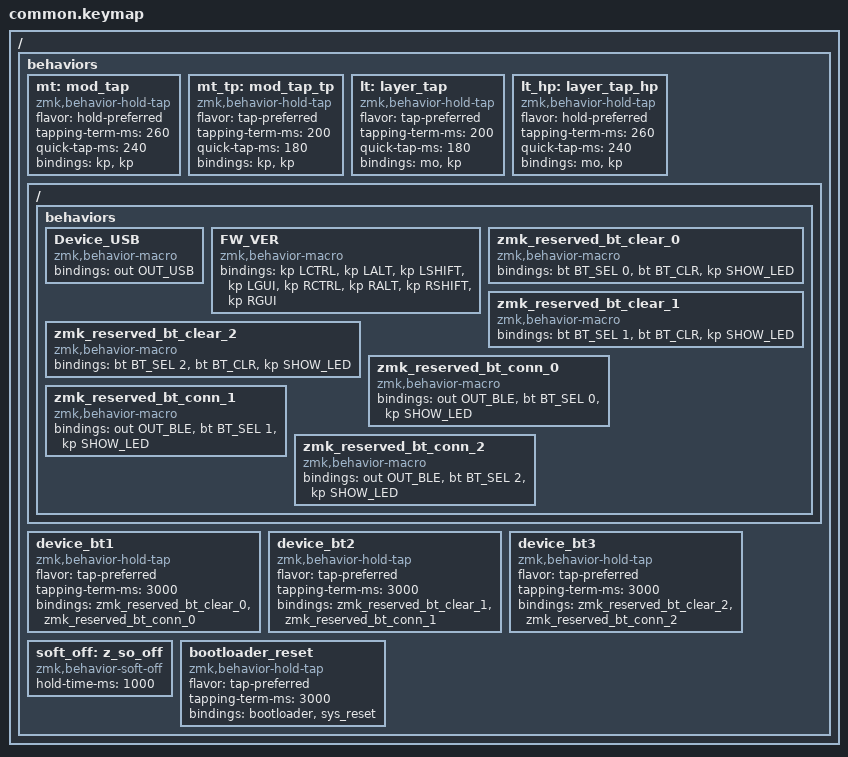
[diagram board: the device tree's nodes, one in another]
/*
 * Copyright (c) 2021 The ZMK Contributors
 *
 * SPDX-License-Identifier: MIT
 */
#define FW_VER zmk_firmware_version_251115
 
#if 0
#define ZMK_BEHAVIORS_OMIT_CAPS_WORD        // &caps_word
#define ZMK_BEHAVIORS_OMIT_KT               // &kt, Key Toggle
#define ZMK_BEHAVIORS_OMIT_KEY_REPEAT       // &key_repeat, Key Repeat
#define ZMK_BEHAVIORS_OMIT_SK               // &sk, Sticky Key
#define ZMK_BEHAVIORS_OMIT_STICKY_LAYER     // &sl, Sticky Layer
#endif

#include <behaviors.dtsi>
#include <dt-bindings/zmk/keys.h>
#include <dt-bindings/zmk/bt.h>
#include <dt-bindings/zmk/outputs.h>

/ {
    behaviors {
        // mt default: hold preferred. Rename it.
        mt: mod_tap {
            compatible = "zmk,behavior-hold-tap";
            #binding-cells = <2>;
            flavor = "hold-preferred";
            tapping-term-ms = <260>;
            quick-tap-ms = <240>;
            bindings = <&kp>, <&kp>;
        };

        // mt_tp tap preferred
        mt_tp: mod_tap_tp {
            compatible = "zmk,behavior-hold-tap";
            #binding-cells = <2>;
            flavor = "tap-preferred";
            tapping-term-ms = <200>;
            quick-tap-ms = <180>;
            bindings = <&kp>, <&kp>;
        };

        // lt default: tap preferred. Rename it.
        lt: layer_tap {
            compatible = "zmk,behavior-hold-tap";
            #binding-cells = <2>;
            flavor = "tap-preferred";
            tapping-term-ms = <200>;
            quick-tap-ms = <180>;
            bindings = <&mo>, <&kp>;
        };

        // lt_hp:  hold preferred
        lt_hp: layer_tap_hp {
            compatible = "zmk,behavior-hold-tap";
            #binding-cells = <2>;
            flavor = "hold-preferred";
            tapping-term-ms = <260>;
            quick-tap-ms = <240>;
            bindings = <&mo>, <&kp>;
        };
        
        #if 1
        ZMK_MACRO(Device_USB, bindings = <&out OUT_USB>;)

        #define SHOW_LED 0xAB //A5-AF Reserved
        ZMK_MACRO(FW_VER, bindings = <&kp LCTRL &kp LALT &kp LSHIFT &kp LGUI &kp RCTRL &kp RALT &kp RSHIFT &kp RGUI>;)
        ZMK_MACRO(zmk_reserved_bt_clear_0, bindings = <&bt BT_SEL 0>, <&bt BT_CLR>, <&kp SHOW_LED>;)
        ZMK_MACRO(zmk_reserved_bt_clear_1, bindings = <&bt BT_SEL 1>, <&bt BT_CLR>, <&kp SHOW_LED>;)
        ZMK_MACRO(zmk_reserved_bt_clear_2, bindings = <&bt BT_SEL 2>, <&bt BT_CLR>, <&kp SHOW_LED>;)
        ZMK_MACRO(zmk_reserved_bt_conn_0,  bindings = <&out OUT_BLE>, <&bt BT_SEL 0>, <&kp SHOW_LED>;)
        ZMK_MACRO(zmk_reserved_bt_conn_1,  bindings = <&out OUT_BLE>, <&bt BT_SEL 1>, <&kp SHOW_LED>;)
        ZMK_MACRO(zmk_reserved_bt_conn_2,  bindings = <&out OUT_BLE>, <&bt BT_SEL 2>, <&kp SHOW_LED>;)

        device_bt1: device_bt1 {
            compatible = "zmk,behavior-hold-tap";
            #binding-cells = <2>;
            flavor = "tap-preferred";
            tapping-term-ms = <3000>;  // delay amount in ms
            bindings = <&zmk_reserved_bt_clear_0>, <&zmk_reserved_bt_conn_0>;
        };
        device_bt2: device_bt2 {
            compatible = "zmk,behavior-hold-tap";
            #binding-cells = <2>;
            flavor = "tap-preferred";
            tapping-term-ms = <3000>;  // delay amount in ms
            bindings = <&zmk_reserved_bt_clear_1>, <&zmk_reserved_bt_conn_1>;
        };
        device_bt3: device_bt3 {
            compatible = "zmk,behavior-hold-tap";
            #binding-cells = <2>;
            flavor = "tap-preferred";
            tapping-term-ms = <3000>;  // delay amount in ms
            bindings = <&zmk_reserved_bt_clear_2>, <&zmk_reserved_bt_conn_2>;
        };
        //
        soft_off: z_so_off {
            compatible = "zmk,behavior-soft-off";
            #binding-cells = <0>;
            hold-time-ms = <1000>;
        };

        bootloader_reset:bootloader_reset {
            compatible = "zmk,behavior-hold-tap";
            #binding-cells = <2>;
            flavor = "tap-preferred";
            tapping-term-ms = <3000>;  // delay amount in ms
            bindings = <&bootloader>, <&sys_reset>;
        };
        #endif
    };
};
